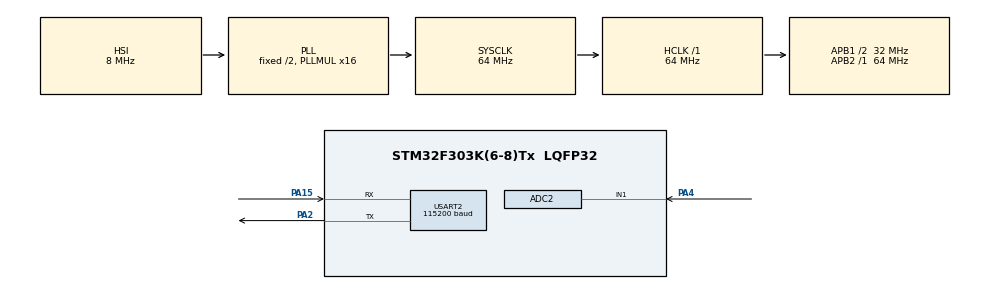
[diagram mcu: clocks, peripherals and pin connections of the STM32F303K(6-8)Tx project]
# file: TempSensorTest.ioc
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Mcu.Family=STM32F3
RCC.CortexFreq_Value=64000000
ADC2.Channel-0\#ChannelRegularConversion=ADC_CHANNEL_1
RCC.SYSCLKSourceVirtual=RCC_SYSCLKSOURCE_PLLCLK
RCC.APB1CLKDivider=RCC_HCLK_DIV2
USART2.BaudRate=115200
ProjectManager.StackSize=0x400
ADC2.ContinuousConvMode=ENABLE
ProjectManager.TargetToolchain=SW4STM32
PA4.Mode=IN1-Single-Ended
RCC.HCLKFreq_Value=64000000
RCC.APB2TimFreq_Value=64000000
RCC.AHBFreq_Value=64000000
RCC.HSE_VALUE=8000000
ADC2.OffsetNumber-0\#ChannelRegularConversion=ADC_OFFSET_NONE
board=custom
USART2.VirtualMode-Asynchronous=VM_ASYNC
PA15.Mode=Asynchronous
RCC.PLLMUL=RCC_PLL_MUL16
RCC.APB2Freq_Value=64000000
Mcu.Name=STM32F303K(6-8)Tx
PA2.Signal=USART2_TX
RCC.SYSCLKFreq_VALUE=64000000
PA4.Signal=ADC2_IN1
Mcu.Package=LQFP32
ADC2.Offset-0\#ChannelRegularConversion=0
ADC2.NbrOfConversionFlag=1
PA15.Signal=USART2_RX
ProjectManager.HeapSize=0x200
ADC2.SamplingTime-0\#ChannelRegularConversion=ADC_SAMPLETIME_1CYCLE_5
RCC.HSI_VALUE=8000000
NVIC.PriorityGroup=NVIC_PRIORITYGROUP_4
RCC.APB1TimFreq_Value=64000000
PA2.Mode=Asynchronous
ADC2.Rank-0\#ChannelRegularConversion=1
RCC.APB1Freq_Value=32000000

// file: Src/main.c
/* USER CODE BEGIN Header */
/**
 ******************************************************************************
 * @file           : main.c
 * @brief          : Main program body
 ******************************************************************************
 * @attention
 *
 * <h2><center>&copy; Copyright (c) 2020 STMicroelectronics.
 * All rights reserved.</center></h2>
 *
 * This software component is licensed by ST under BSD 3-Clause license,
 * the "License"; You may not use this file except in compliance with the
 * License. You may obtain a copy of the License at:
 *                        opensource.org/licenses/BSD-3-Clause
 *
 ******************************************************************************
 */
/* USER CODE END Header */

#include "main.h"

ADC_HandleTypeDef hadc2;

UART_HandleTypeDef huart2;

void SystemClock_Config(void);
static void MX_GPIO_Init(void);
static void MX_USART2_UART_Init(void);
static void MX_ADC2_Init(void);

/* USER CODE BEGIN 0 */
#ifdef __GNUC__
#define PUTCHAR_PROTOTYPE int __io_putchar(int ch)
#else
#define PUTCHAR_PROTOTYPE int fputc(int ch, FILE *f)
#endif /* __GNUC__ */
void __io_putchar(uint8_t ch) {
	HAL_UART_Transmit(&huart2, &ch, 1, 1);
}
/* USER CODE END 0 */

int main(void) {

	/* MCU Configuration--------------------------------------------------------*/

	/* Reset of all peripherals, Initializes the Flash interface and the Systick. */
	HAL_Init();

	/* Configure the system clock */
	SystemClock_Config();

	/* Initialize all configured peripherals */
	MX_GPIO_Init();
	MX_USART2_UART_Init();
	MX_ADC2_Init();

	/* Infinite loop */
	/* USER CODE BEGIN WHILE */
	HAL_ADCEx_Calibration_Start(&hadc2, ADC_SINGLE_ENDED);
	HAL_ADC_Start(&hadc2);
	int adc1_val = 0;

	while (1) {
		if (HAL_ADC_PollForConversion(&hadc2, 10) == HAL_OK) {
			adc1_val = HAL_ADC_GetValue(&hadc2);
			printf("%d\n\r", adc1_val);
		}
		HAL_Delay(1000);
		/* USER CODE END WHILE */

		/* USER CODE BEGIN 3 */
	}
	HAL_ADC_Stop(&hadc2);
	/* USER CODE END 3 */
}

void SystemClock_Config(void) {
	RCC_OscInitTypeDef RCC_OscInitStruct = { 0 };
	RCC_ClkInitTypeDef RCC_ClkInitStruct = { 0 };
	RCC_PeriphCLKInitTypeDef PeriphClkInit = { 0 };

	/** Initializes the CPU, AHB and APB busses clocks
	 */
	RCC_OscInitStruct.OscillatorType = RCC_OSCILLATORTYPE_HSI;
	RCC_OscInitStruct.HSIState = RCC_HSI_ON;
	RCC_OscInitStruct.HSICalibrationValue = RCC_HSICALIBRATION_DEFAULT;
	RCC_OscInitStruct.PLL.PLLState = RCC_PLL_ON;
	RCC_OscInitStruct.PLL.PLLSource = RCC_PLLSOURCE_HSI;
	RCC_OscInitStruct.PLL.PLLMUL = RCC_PLL_MUL16;
	if (HAL_RCC_OscConfig(&RCC_OscInitStruct) != HAL_OK) {
		Error_Handler();
	}
	/** Initializes the CPU, AHB and APB busses clocks
	 */
	RCC_ClkInitStruct.ClockType = RCC_CLOCKTYPE_HCLK | RCC_CLOCKTYPE_SYSCLK
			| RCC_CLOCKTYPE_PCLK1 | RCC_CLOCKTYPE_PCLK2;
	RCC_ClkInitStruct.SYSCLKSource = RCC_SYSCLKSOURCE_PLLCLK;
	RCC_ClkInitStruct.AHBCLKDivider = RCC_SYSCLK_DIV1;
	RCC_ClkInitStruct.APB1CLKDivider = RCC_HCLK_DIV2;
	RCC_ClkInitStruct.APB2CLKDivider = RCC_HCLK_DIV1;

	if (HAL_RCC_ClockConfig(&RCC_ClkInitStruct, FLASH_LATENCY_2) != HAL_OK) {
		Error_Handler();
	}
	PeriphClkInit.PeriphClockSelection = RCC_PERIPHCLK_ADC12;
	PeriphClkInit.Adc12ClockSelection = RCC_ADC12PLLCLK_DIV1;
	if (HAL_RCCEx_PeriphCLKConfig(&PeriphClkInit) != HAL_OK) {
		Error_Handler();
	}
}

static void MX_ADC2_Init(void) {

	ADC_ChannelConfTypeDef sConfig = { 0 };

	/** Common config
	 */
	hadc2.Instance = ADC2;
	hadc2.Init.ClockPrescaler = ADC_CLOCK_ASYNC_DIV1;
	hadc2.Init.Resolution = ADC_RESOLUTION_12B;
	hadc2.Init.ScanConvMode = ADC_SCAN_DISABLE;
	hadc2.Init.ContinuousConvMode = ENABLE;
	hadc2.Init.DiscontinuousConvMode = DISABLE;
	hadc2.Init.ExternalTrigConvEdge = ADC_EXTERNALTRIGCONVEDGE_NONE;
	hadc2.Init.ExternalTrigConv = ADC_SOFTWARE_START;
	hadc2.Init.DataAlign = ADC_DATAALIGN_RIGHT;
	hadc2.Init.NbrOfConversion = 1;
	hadc2.Init.DMAContinuousRequests = DISABLE;
	hadc2.Init.EOCSelection = ADC_EOC_SINGLE_CONV;
	hadc2.Init.LowPowerAutoWait = DISABLE;
	hadc2.Init.Overrun = ADC_OVR_DATA_OVERWRITTEN;
	if (HAL_ADC_Init(&hadc2) != HAL_OK) {
		Error_Handler();
	}
	/** Configure Regular Channel
	 */
	sConfig.Channel = ADC_CHANNEL_1;
	sConfig.Rank = ADC_REGULAR_RANK_1;
	sConfig.SingleDiff = ADC_SINGLE_ENDED;
	sConfig.SamplingTime = ADC_SAMPLETIME_1CYCLE_5;
	sConfig.OffsetNumber = ADC_OFFSET_NONE;
	sConfig.Offset = 0;
	if (HAL_ADC_ConfigChannel(&hadc2, &sConfig) != HAL_OK) {
		Error_Handler();
	}

}

static void MX_USART2_UART_Init(void) {

	huart2.Instance = USART2;
	huart2.Init.BaudRate = 115200;
	huart2.Init.WordLength = UART_WORDLENGTH_8B;
	huart2.Init.StopBits = UART_STOPBITS_1;
	huart2.Init.Parity = UART_PARITY_NONE;
	huart2.Init.Mode = UART_MODE_TX_RX;
	huart2.Init.HwFlowCtl = UART_HWCONTROL_NONE;
	huart2.Init.OverSampling = UART_OVERSAMPLING_16;
	huart2.Init.OneBitSampling = UART_ONE_BIT_SAMPLE_DISABLE;
	huart2.AdvancedInit.AdvFeatureInit = UART_ADVFEATURE_NO_INIT;
	if (HAL_UART_Init(&huart2) != HAL_OK) {
		Error_Handler();
	}

}

static void MX_GPIO_Init(void) {

	/* GPIO Ports Clock Enable */
	__HAL_RCC_GPIOA_CLK_ENABLE()
	;

}

void Error_Handler(void) {
}

/************************ (C) COPYRIGHT STMicroelectronics *****END OF FILE****/
